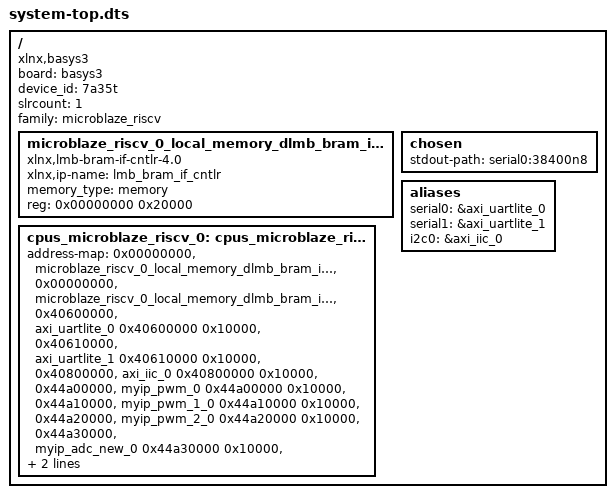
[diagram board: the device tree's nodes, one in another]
/dts-v1/;
#include "pl.dtsi"
/ {
	board = "basys3";
	compatible = "xlnx,basys3";
	device_id = "7a35t";
	#address-cells = <1>;
	#size-cells = <1>;
	slrcount = <1>;
	family = "microblaze_riscv";
	microblaze_riscv_0_local_memory_dlmb_bram_if_cntlr_memory: memory@0 {
		compatible = "xlnx,lmb-bram-if-cntlr-4.0";
		xlnx,ip-name = "lmb_bram_if_cntlr";
		device_type = "memory";
		memory_type = "memory";
		reg = <0x00000000 0x20000>;
	};
	chosen {
		stdout-path = "serial0:38400n8";
	};
	aliases {
		serial0 = &axi_uartlite_0;
		serial1 = &axi_uartlite_1;
		i2c0 = &axi_iic_0;
	};
	cpus_microblaze_riscv_0: cpus_microblaze_riscv@0 {
		address-map = <0x00000000 &microblaze_riscv_0_local_memory_dlmb_bram_if_cntlr_memory 0x00000000 0x20000>, 
			      <0x00000000 &microblaze_riscv_0_local_memory_dlmb_bram_if_cntlr 0x00000000 0x20000>, 
			      <0x40600000 &axi_uartlite_0 0x40600000 0x10000>, 
			      <0x40610000 &axi_uartlite_1 0x40610000 0x10000>, 
			      <0x40800000 &axi_iic_0 0x40800000 0x10000>, 
			      <0x44a00000 &myip_pwm_0 0x44a00000 0x10000>, 
			      <0x44a10000 &myip_pwm_1_0 0x44a10000 0x10000>, 
			      <0x44a20000 &myip_pwm_2_0 0x44a20000 0x10000>, 
			      <0x44a30000 &myip_adc_new_0 0x44a30000 0x10000>, 
			      <0x44a40000 &myip_btn_0 0x44a40000 0x10000>, 
			      <0x44a50000 &myip_btn_1 0x44a50000 0x10000>;
		#ranges-address-cells = <0x1>;
		#ranges-size-cells = <0x1>;
	};
};
